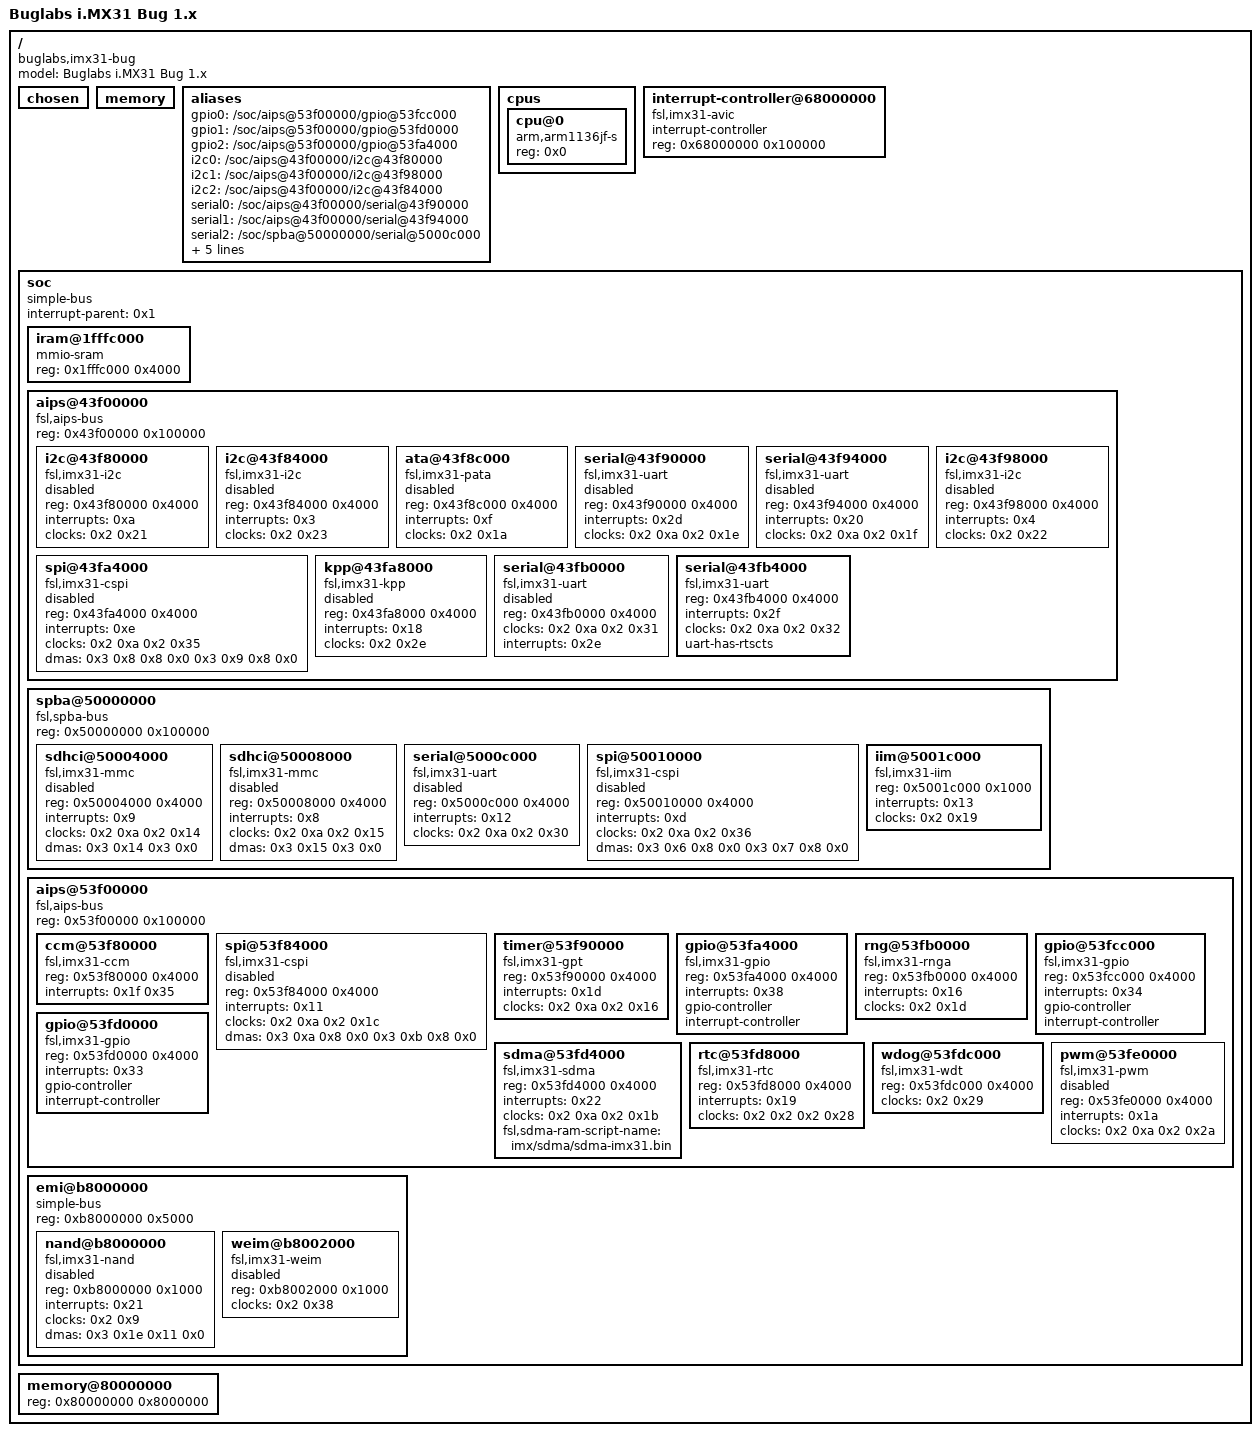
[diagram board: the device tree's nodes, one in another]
/*
 * The code contained herein is licensed under the GNU General Public
 * License. You may obtain a copy of the GNU General Public License
 * Version 2 or later at the following locations:
 *
 * http://www.opensource.org/licenses/gpl-license.html
 * http://www.gnu.org/copyleft/gpl.html
 *
 * @TAG(OTHER_GPL)
 */

/dts-v1/;

/ {
	#address-cells = <0x1>;
	#size-cells = <0x1>;
	model = "Buglabs i.MX31 Bug 1.x";
	compatible = "buglabs,imx31-bug", "fsl,imx31";

	chosen {
	};

	memory {
		device_type = "memory";
	};

	aliases {
		gpio0 = "/soc/aips@53f00000/gpio@53fcc000";
		gpio1 = "/soc/aips@53f00000/gpio@53fd0000";
		gpio2 = "/soc/aips@53f00000/gpio@53fa4000";
		i2c0 = "/soc/aips@43f00000/i2c@43f80000";
		i2c1 = "/soc/aips@43f00000/i2c@43f98000";
		i2c2 = "/soc/aips@43f00000/i2c@43f84000";
		serial0 = "/soc/aips@43f00000/serial@43f90000";
		serial1 = "/soc/aips@43f00000/serial@43f94000";
		serial2 = "/soc/spba@50000000/serial@5000c000";
		serial3 = "/soc/aips@43f00000/serial@43fb0000";
		serial4 = "/soc/aips@43f00000/serial@43fb4000";
		spi0 = "/soc/aips@43f00000/spi@43fa4000";
		spi1 = "/soc/spba@50000000/spi@50010000";
		spi2 = "/soc/aips@53f00000/spi@53f84000";
	};

	cpus {
		#address-cells = <0x1>;
		#size-cells = <0x0>;

		cpu@0 {
			compatible = "arm,arm1136jf-s";
			device_type = "cpu";
			reg = <0x0>;
		};
	};

	interrupt-controller@68000000 {
		compatible = "fsl,imx31-avic", "fsl,avic";
		interrupt-controller;
		#interrupt-cells = <0x1>;
		reg = <0x68000000 0x100000>;
		phandle = <0x1>;
	};

	soc {
		#address-cells = <0x1>;
		#size-cells = <0x1>;
		compatible = "simple-bus";
		interrupt-parent = <0x1>;
		ranges;

		iram@1fffc000 {
			compatible = "mmio-sram";
			reg = <0x1fffc000 0x4000>;
			#address-cells = <0x1>;
			#size-cells = <0x1>;
			ranges = <0x0 0x1fffc000 0x4000>;
		};

		aips@43f00000 {
			compatible = "fsl,aips-bus", "simple-bus";
			#address-cells = <0x1>;
			#size-cells = <0x1>;
			reg = <0x43f00000 0x100000>;
			ranges;

			i2c@43f80000 {
				compatible = "fsl,imx31-i2c", "fsl,imx21-i2c";
				reg = <0x43f80000 0x4000>;
				interrupts = <0xa>;
				clocks = <0x2 0x21>;
				#address-cells = <0x1>;
				#size-cells = <0x0>;
				status = "disabled";
			};

			i2c@43f84000 {
				compatible = "fsl,imx31-i2c", "fsl,imx21-i2c";
				reg = <0x43f84000 0x4000>;
				interrupts = <0x3>;
				clocks = <0x2 0x23>;
				#address-cells = <0x1>;
				#size-cells = <0x0>;
				status = "disabled";
			};

			ata@43f8c000 {
				compatible = "fsl,imx31-pata", "fsl,imx27-pata";
				reg = <0x43f8c000 0x4000>;
				interrupts = <0xf>;
				clocks = <0x2 0x1a>;
				status = "disabled";
			};

			serial@43f90000 {
				compatible = "fsl,imx31-uart", "fsl,imx21-uart";
				reg = <0x43f90000 0x4000>;
				interrupts = <0x2d>;
				clocks = <0x2 0xa 0x2 0x1e>;
				clock-names = "ipg", "per";
				status = "disabled";
			};

			serial@43f94000 {
				compatible = "fsl,imx31-uart", "fsl,imx21-uart";
				reg = <0x43f94000 0x4000>;
				interrupts = <0x20>;
				clocks = <0x2 0xa 0x2 0x1f>;
				clock-names = "ipg", "per";
				status = "disabled";
			};

			i2c@43f98000 {
				compatible = "fsl,imx31-i2c", "fsl,imx21-i2c";
				reg = <0x43f98000 0x4000>;
				interrupts = <0x4>;
				clocks = <0x2 0x22>;
				#address-cells = <0x1>;
				#size-cells = <0x0>;
				status = "disabled";
			};

			spi@43fa4000 {
				compatible = "fsl,imx31-cspi";
				reg = <0x43fa4000 0x4000>;
				interrupts = <0xe>;
				clocks = <0x2 0xa 0x2 0x35>;
				clock-names = "ipg", "per";
				dmas = <0x3 0x8 0x8 0x0 0x3 0x9 0x8 0x0>;
				dma-names = "rx", "tx";
				#address-cells = <0x1>;
				#size-cells = <0x0>;
				status = "disabled";
			};

			kpp@43fa8000 {
				compatible = "fsl,imx31-kpp", "fsl,imx21-kpp";
				reg = <0x43fa8000 0x4000>;
				interrupts = <0x18>;
				clocks = <0x2 0x2e>;
				status = "disabled";
			};

			serial@43fb0000 {
				compatible = "fsl,imx31-uart", "fsl,imx21-uart";
				reg = <0x43fb0000 0x4000>;
				clocks = <0x2 0xa 0x2 0x31>;
				clock-names = "ipg", "per";
				interrupts = <0x2e>;
				status = "disabled";
			};

			serial@43fb4000 {
				compatible = "fsl,imx31-uart", "fsl,imx21-uart";
				reg = <0x43fb4000 0x4000>;
				interrupts = <0x2f>;
				clocks = <0x2 0xa 0x2 0x32>;
				clock-names = "ipg", "per";
				status = "okay";
				uart-has-rtscts;
			};
		};

		spba@50000000 {
			compatible = "fsl,spba-bus", "simple-bus";
			#address-cells = <0x1>;
			#size-cells = <0x1>;
			reg = <0x50000000 0x100000>;
			ranges;

			sdhci@50004000 {
				compatible = "fsl,imx31-mmc";
				reg = <0x50004000 0x4000>;
				interrupts = <0x9>;
				clocks = <0x2 0xa 0x2 0x14>;
				clock-names = "ipg", "per";
				dmas = <0x3 0x14 0x3 0x0>;
				dma-names = "rx-tx";
				status = "disabled";
			};

			sdhci@50008000 {
				compatible = "fsl,imx31-mmc";
				reg = <0x50008000 0x4000>;
				interrupts = <0x8>;
				clocks = <0x2 0xa 0x2 0x15>;
				clock-names = "ipg", "per";
				dmas = <0x3 0x15 0x3 0x0>;
				dma-names = "rx-tx";
				status = "disabled";
			};

			serial@5000c000 {
				compatible = "fsl,imx31-uart", "fsl,imx21-uart";
				reg = <0x5000c000 0x4000>;
				interrupts = <0x12>;
				clocks = <0x2 0xa 0x2 0x30>;
				clock-names = "ipg", "per";
				status = "disabled";
			};

			spi@50010000 {
				compatible = "fsl,imx31-cspi";
				reg = <0x50010000 0x4000>;
				interrupts = <0xd>;
				clocks = <0x2 0xa 0x2 0x36>;
				clock-names = "ipg", "per";
				dmas = <0x3 0x6 0x8 0x0 0x3 0x7 0x8 0x0>;
				dma-names = "rx", "tx";
				#address-cells = <0x1>;
				#size-cells = <0x0>;
				status = "disabled";
			};

			iim@5001c000 {
				compatible = "fsl,imx31-iim", "fsl,imx27-iim";
				reg = <0x5001c000 0x1000>;
				interrupts = <0x13>;
				clocks = <0x2 0x19>;
			};
		};

		aips@53f00000 {
			compatible = "fsl,aips-bus", "simple-bus";
			#address-cells = <0x1>;
			#size-cells = <0x1>;
			reg = <0x53f00000 0x100000>;
			ranges;

			ccm@53f80000 {
				compatible = "fsl,imx31-ccm";
				reg = <0x53f80000 0x4000>;
				interrupts = <0x1f 0x35>;
				#clock-cells = <0x1>;
				phandle = <0x2>;
			};

			spi@53f84000 {
				compatible = "fsl,imx31-cspi";
				reg = <0x53f84000 0x4000>;
				interrupts = <0x11>;
				clocks = <0x2 0xa 0x2 0x1c>;
				clock-names = "ipg", "per";
				dmas = <0x3 0xa 0x8 0x0 0x3 0xb 0x8 0x0>;
				dma-names = "rx", "tx";
				#address-cells = <0x1>;
				#size-cells = <0x0>;
				status = "disabled";
			};

			timer@53f90000 {
				compatible = "fsl,imx31-gpt";
				reg = <0x53f90000 0x4000>;
				interrupts = <0x1d>;
				clocks = <0x2 0xa 0x2 0x16>;
				clock-names = "ipg", "per";
			};

			gpio@53fa4000 {
				compatible = "fsl,imx31-gpio";
				reg = <0x53fa4000 0x4000>;
				interrupts = <0x38>;
				gpio-controller;
				#gpio-cells = <0x2>;
				interrupt-controller;
				#interrupt-cells = <0x2>;
			};

			rng@53fb0000 {
				compatible = "fsl,imx31-rnga";
				reg = <0x53fb0000 0x4000>;
				interrupts = <0x16>;
				clocks = <0x2 0x1d>;
			};

			gpio@53fcc000 {
				compatible = "fsl,imx31-gpio";
				reg = <0x53fcc000 0x4000>;
				interrupts = <0x34>;
				gpio-controller;
				#gpio-cells = <0x2>;
				interrupt-controller;
				#interrupt-cells = <0x2>;
			};

			gpio@53fd0000 {
				compatible = "fsl,imx31-gpio";
				reg = <0x53fd0000 0x4000>;
				interrupts = <0x33>;
				gpio-controller;
				#gpio-cells = <0x2>;
				interrupt-controller;
				#interrupt-cells = <0x2>;
			};

			sdma@53fd4000 {
				compatible = "fsl,imx31-sdma";
				reg = <0x53fd4000 0x4000>;
				interrupts = <0x22>;
				clocks = <0x2 0xa 0x2 0x1b>;
				clock-names = "ipg", "ahb";
				#dma-cells = <0x3>;
				fsl,sdma-ram-script-name = "imx/sdma/sdma-imx31.bin";
				phandle = <0x3>;
			};

			rtc@53fd8000 {
				compatible = "fsl,imx31-rtc", "fsl,imx21-rtc";
				reg = <0x53fd8000 0x4000>;
				interrupts = <0x19>;
				clocks = <0x2 0x2 0x2 0x28>;
				clock-names = "ref", "ipg";
			};

			wdog@53fdc000 {
				compatible = "fsl,imx31-wdt", "fsl,imx21-wdt";
				reg = <0x53fdc000 0x4000>;
				clocks = <0x2 0x29>;
			};

			pwm@53fe0000 {
				compatible = "fsl,imx31-pwm", "fsl,imx27-pwm";
				reg = <0x53fe0000 0x4000>;
				interrupts = <0x1a>;
				clocks = <0x2 0xa 0x2 0x2a>;
				clock-names = "ipg", "per";
				#pwm-cells = <0x2>;
				status = "disabled";
			};
		};

		emi@b8000000 {
			compatible = "simple-bus";
			reg = <0xb8000000 0x5000>;
			ranges;
			#address-cells = <0x1>;
			#size-cells = <0x1>;

			nand@b8000000 {
				compatible = "fsl,imx31-nand", "fsl,imx27-nand";
				reg = <0xb8000000 0x1000>;
				interrupts = <0x21>;
				clocks = <0x2 0x9>;
				dmas = <0x3 0x1e 0x11 0x0>;
				dma-names = "rx-tx";
				#address-cells = <0x1>;
				#size-cells = <0x1>;
				status = "disabled";
			};

			weim@b8002000 {
				compatible = "fsl,imx31-weim", "fsl,imx27-weim";
				reg = <0xb8002000 0x1000>;
				clocks = <0x2 0x38>;
				#address-cells = <0x2>;
				#size-cells = <0x1>;
				ranges = <0x0 0x0 0xa0000000 0x8000000 0x1 0x0 0xa8000000 0x8000000 0x2 0x0 0xb0000000 0x2000000 0x3 0x0 0xb2000000 0x2000000 0x4 0x0 0xb4000000 0x2000000 0x5 0x0 0xb6000000 0x2000000>;
				status = "disabled";
			};
		};
	};

	memory@80000000 {
		reg = <0x80000000 0x8000000>;
	};
};
